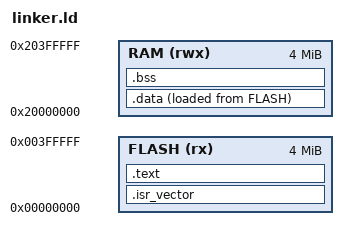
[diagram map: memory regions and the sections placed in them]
ENTRY(Reset_Handler)

MEMORY {
    FLASH (rx)  : ORIGIN = 0x00000000, LENGTH = 4M
    RAM   (rwx) : ORIGIN = 0x20000000, LENGTH = 4M
}

SECTIONS {
    .isr_vector : {
        KEEP(*(.isr_vector))
    } > FLASH

    .text : {
        *(.text*)
        *(.rodata*)
    } > FLASH

    .data : {
        _sdata = .;
        *(.data*)
        _edata = .;
    } > RAM AT > FLASH
    _sidata = LOADADDR(.data);

    .bss : {
        __bss_start__ = .;
        _sbss = .;
        *(.bss*)
        *(COMMON)
        _ebss = .;
        __bss_end__ = .;
    } > RAM

    . = ALIGN(8);
    __end__ = .;
    end = .;

    _stack_top = ORIGIN(RAM) + LENGTH(RAM);
}
